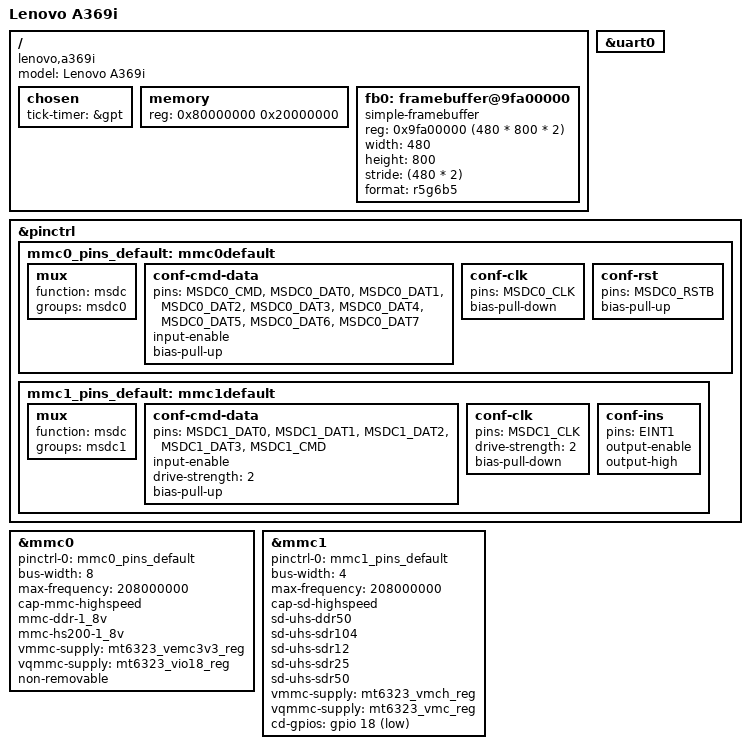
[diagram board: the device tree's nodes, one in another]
/dts-v1/;
#include <dt-bindings/input/input.h>
#include <dt-bindings/gpio/gpio.h>
#include "mt6572.dtsi"
#include "mt6323.dtsi"
#include "skeleton.dtsi"

/ {
  model = "Lenovo A369i";
  compatible = "lenovo,a369i";

  chosen {
    tick-timer = &gpt;
  };

  memory {
    #address-cells = <1>;
    #size-cells = <1>;
    device_type = "memory";
    reg = <0x80000000 0x20000000>;
  };

  /* HACK: Use framebuffer set up by previous LK bootloader */
  fb0: framebuffer@9fa00000 {
    compatible = "simple-framebuffer";
    reg = <0x9fa00000 (480 * 800 * 2)>;
    width = <480>;
    height = <800>;
    stride = <(480 * 2)>;
    format = "r5g6b5";
    status = "okay";
  };

  /* Vol +/- are connected GPIO, PWRKEY is connected to PMIC */
  /*gpio-keys {
    compatible = "gpio-keys";

    vol-up {
      label = "Volume Up";
      linux,code = <KEY_VOLUMEUP>;
      gpios = <&gpio 110 GPIO_ACTIVE_LOW>;
    };

    vol-down {
      label = "Volume Down";
      linux,code = <KEY_VOLUMEDOWN>;
      gpios = <&gpio 107 GPIO_ACTIVE_LOW>;
    };
  };*/
};

&uart0 {
  status = "okay";
};

&pinctrl {
  mmc0_pins_default: mmc0default {
    mux {
      function = "msdc";
      groups =  "msdc0";
    };

    conf-cmd-data {
      pins = "MSDC0_CMD", "MSDC0_DAT0", "MSDC0_DAT1",
             "MSDC0_DAT2", "MSDC0_DAT3", "MSDC0_DAT4",
             "MSDC0_DAT5", "MSDC0_DAT6", "MSDC0_DAT7";
      input-enable;
      bias-pull-up;
    };

    conf-clk {
      pins = "MSDC0_CLK";
      bias-pull-down;
    };

    conf-rst {
      pins = "MSDC0_RSTB";
      bias-pull-up;
    };
  };

  mmc1_pins_default: mmc1default {
    mux {
      function = "msdc";
      groups =  "msdc1";
    };

    conf-cmd-data {
      pins = "MSDC1_DAT0", "MSDC1_DAT1", "MSDC1_DAT2",
             "MSDC1_DAT3", "MSDC1_CMD";
      input-enable;
      drive-strength = <2>;
      bias-pull-up;
    };

    conf-clk {
      pins = "MSDC1_CLK";
      drive-strength = <2>;
      bias-pull-down;
    };

    conf-ins {
      pins = "EINT1";
      output-enable;
      output-high;
    };
  };
};

&mmc0 {
  pinctrl-names = "default";
  pinctrl-0 = <&mmc0_pins_default>;
  bus-width = <8>;
  max-frequency = <208000000>;
  cap-mmc-highspeed;
  mmc-ddr-1_8v;
  mmc-hs200-1_8v;
  vmmc-supply = <&mt6323_vemc3v3_reg>;
  vqmmc-supply = <&mt6323_vio18_reg>;
  non-removable;
  status = "okay";
};

&mmc1 {
  pinctrl-names = "default";
  pinctrl-0 = <&mmc1_pins_default>;
  bus-width = <4>;
  max-frequency = <208000000>;
  cap-sd-highspeed;
  sd-uhs-ddr50;
  sd-uhs-sdr104;
  sd-uhs-sdr12;
  sd-uhs-sdr25;
  sd-uhs-sdr50;
  vmmc-supply = <&mt6323_vmch_reg>;
  vqmmc-supply = <&mt6323_vmc_reg>;
  cd-gpios = <&gpio 18 GPIO_ACTIVE_LOW>;
  status = "okay";
};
